VERSION "MG Windsor EV PRO - uCANdo profile (derived from the MG Commute pack, same platform)"

NS_ :

BS_:

BU_:

BO_ 288 HSC_Odometer: 5 Vector__XXX
 SG_ Odometer : 7|32@0+ (0.015625,0) [0|67108864] "km" Vector__XXX

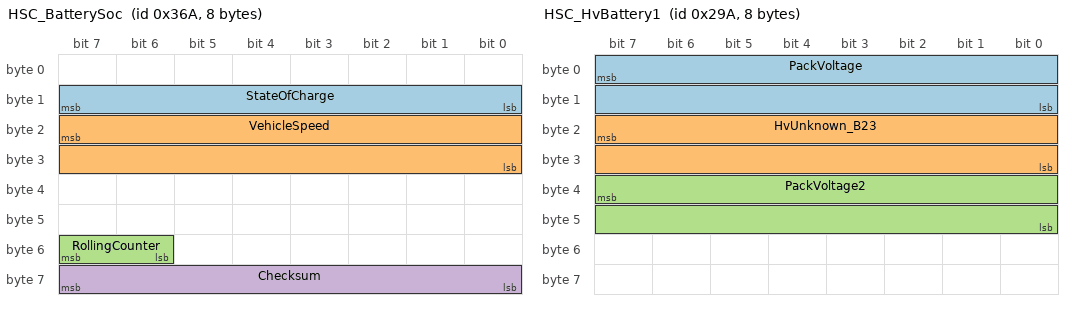
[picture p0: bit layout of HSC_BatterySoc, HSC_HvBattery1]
BO_ 874 HSC_BatterySoc: 8 Vector__XXX
 SG_ StateOfCharge : 15|8@0+ (0.5,0) [0|127.5] "%" Vector__XXX
 SG_ VehicleSpeed : 23|16@0+ (0.015625,0) [0|1023] "km/h" Vector__XXX
 SG_ RollingCounter : 55|2@0+ (1,0) [0|3] "" Vector__XXX
 SG_ Checksum : 63|8@0+ (1,0) [0|255] "" Vector__XXX

BO_ 364 HSC_VehicleSpeedHiRes: 8 Vector__XXX
 SG_ VehicleSpeedSigned : 23|16@0+ (0.01,-327.68) [-327.68|327.67] "km/h" Vector__XXX

BO_ 1221 HSC_RangeToEmpty: 8 Vector__XXX
 SG_ RangeToEmpty : 10|11@0+ (1,0) [0|2047] "km" Vector__XXX

BO_ 666 HSC_HvBattery1: 8 Vector__XXX
 SG_ PackVoltage : 7|16@0+ (0.1,0) [0|1000] "V" Vector__XXX
 SG_ HvUnknown_B23 : 23|16@0+ (0.1,0) [0|1000] "V" Vector__XXX
 SG_ PackVoltage2 : 39|16@0+ (0.1,0) [0|1000] "V" Vector__XXX

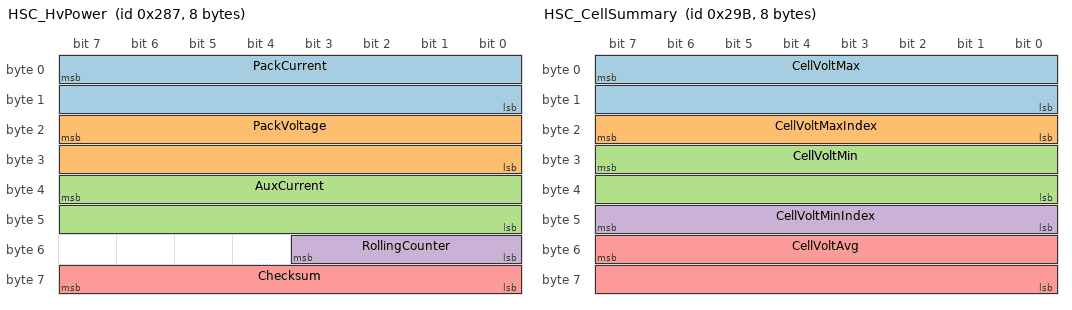
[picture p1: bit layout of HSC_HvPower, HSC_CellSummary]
BO_ 647 HSC_HvPower: 8 Vector__XXX
 SG_ PackCurrent : 7|16@0+ (0.1,-1000) [-1000|5535] "A" Vector__XXX
 SG_ PackVoltage : 23|16@0+ (0.1,0) [0|1000] "V" Vector__XXX
 SG_ AuxCurrent : 39|16@0+ (0.1,-1000) [-1000|5535] "A" Vector__XXX
 SG_ RollingCounter : 51|4@0+ (1,0) [0|15] "" Vector__XXX
 SG_ Checksum : 63|8@0+ (1,0) [0|255] "" Vector__XXX

BO_ 644 HSC_HvBattery2: 8 Vector__XXX
 SG_ PackVoltage : 23|16@0+ (0.1,0) [0|1000] "V" Vector__XXX

BO_ 667 HSC_CellSummary: 8 Vector__XXX
 SG_ CellVoltMax : 7|16@0+ (0.001,0) [0|65.535] "V" Vector__XXX
 SG_ CellVoltMaxIndex : 23|8@0+ (1,0) [0|255] "" Vector__XXX
 SG_ CellVoltMin : 31|16@0+ (0.001,0) [0|65.535] "V" Vector__XXX
 SG_ CellVoltMinIndex : 47|8@0+ (1,0) [0|255] "" Vector__XXX
 SG_ CellVoltAvg : 55|16@0+ (0.001,0) [0|65.535] "V" Vector__XXX

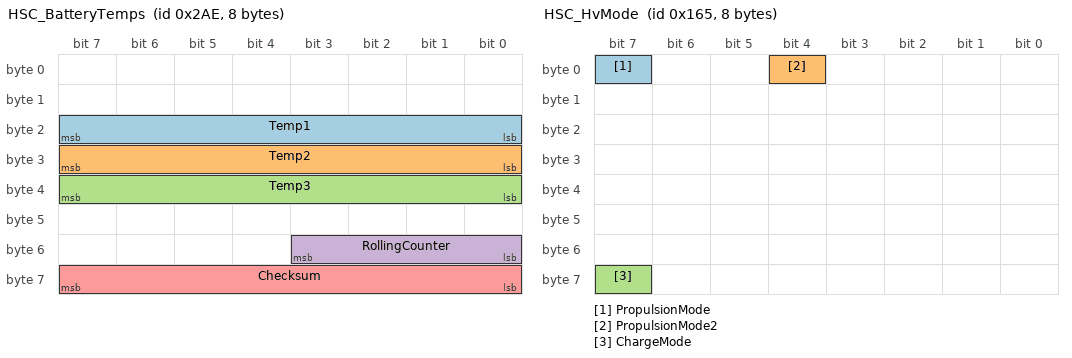
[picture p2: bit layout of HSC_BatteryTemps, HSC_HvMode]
BO_ 686 HSC_BatteryTemps: 8 Vector__XXX
 SG_ Temp1 : 23|8@0+ (1,-40) [-40|215] "degC" Vector__XXX
 SG_ Temp2 : 31|8@0+ (1,-40) [-40|215] "degC" Vector__XXX
 SG_ Temp3 : 39|8@0+ (1,-40) [-40|215] "degC" Vector__XXX
 SG_ RollingCounter : 51|4@0+ (1,0) [0|15] "" Vector__XXX
 SG_ Checksum : 63|8@0+ (1,0) [0|255] "" Vector__XXX

BO_ 1465 HSC_BatterySoh: 8 Vector__XXX
 SG_ SohPercent : 39|8@0+ (1,0) [0|255] "%" Vector__XXX
 SG_ SocPercent : 47|8@0+ (1,0) [0|255] "%" Vector__XXX

BO_ 878 HSC_ChargeTimer: 8 Vector__XXX
 SG_ TimeToFullCharge : 15|16@0+ (1,0) [0|65535] "min" Vector__XXX

BO_ 661 HSC_ChargeStatus: 8 Vector__XXX
 SG_ ChargingActive : 28|1@0+ (1,0) [0|1] "" Vector__XXX
 SG_ ChargerCableStatus : 10|2@0+ (1,0) [0|3] "" Vector__XXX

BO_ 1158 HSC_CellTemps: 8 Vector__XXX
 SG_ CellTemp_B6 : 55|8@0+ (1,-40) [-40|215] "degC" Vector__XXX
 SG_ CellTemp_B7 : 63|8@0+ (1,-40) [-40|215] "degC" Vector__XXX

BO_ 840 HSC_VehicleSpeed3: 6 Vector__XXX
 SG_ VehicleSpeed3 : 7|16@0+ (0.02,0) [0|1310] "km/h" Vector__XXX

BO_ 357 HSC_HvMode: 8 Vector__XXX
 SG_ PropulsionMode : 7|1@0+ (1,0) [0|1] "" Vector__XXX
 SG_ PropulsionMode2 : 4|1@0+ (1,0) [0|1] "" Vector__XXX
 SG_ ChargeMode : 63|1@0+ (1,0) [0|1] "" Vector__XXX

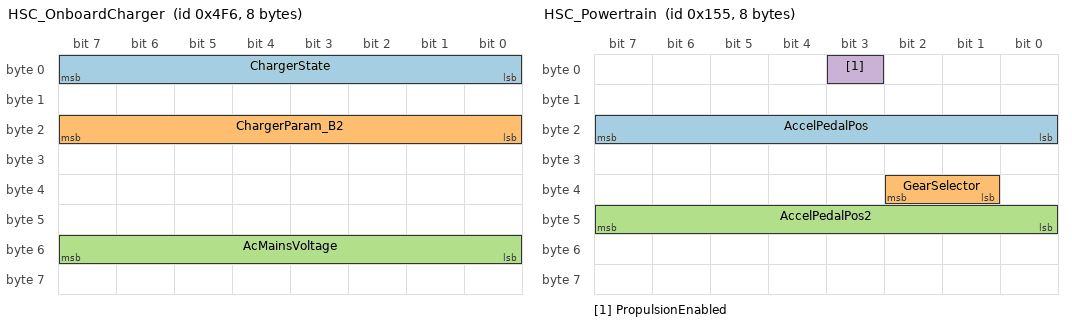
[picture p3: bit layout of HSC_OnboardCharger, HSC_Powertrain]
BO_ 1270 HSC_OnboardCharger: 8 Vector__XXX
 SG_ ChargerState : 7|8@0+ (1,0) [0|255] "" Vector__XXX
 SG_ ChargerParam_B2 : 23|8@0+ (1,0) [0|255] "" Vector__XXX
 SG_ AcMainsVoltage : 55|8@0+ (1,0) [0|255] "" Vector__XXX

BO_ 341 HSC_Powertrain: 8 Vector__XXX
 SG_ AccelPedalPos : 23|8@0+ (1,0) [0|100] "%" Vector__XXX
 SG_ GearSelector : 34|2@0+ (1,0) [0|3] "" Vector__XXX
 SG_ AccelPedalPos2 : 47|8@0+ (1,0) [0|100] "%" Vector__XXX
 SG_ PropulsionEnabled : 3|1@0+ (1,0) [0|1] "" Vector__XXX

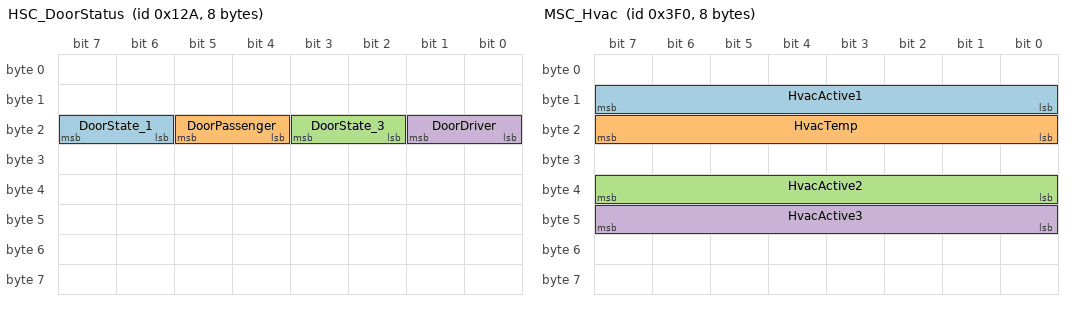
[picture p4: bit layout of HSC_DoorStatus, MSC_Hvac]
BO_ 298 HSC_DoorStatus: 8 Vector__XXX
 SG_ DoorState_1 : 23|2@0+ (1,0) [0|3] "" Vector__XXX
 SG_ DoorPassenger : 21|2@0+ (1,0) [0|3] "" Vector__XXX
 SG_ DoorState_3 : 19|2@0+ (1,0) [0|3] "" Vector__XXX
 SG_ DoorDriver : 17|2@0+ (1,0) [0|3] "" Vector__XXX

BO_ 225 HSC_SeatBelt: 8 Vector__XXX
 SG_ DriverSeatBelt : 11|1@0+ (1,0) [0|1] "" Vector__XXX
 SG_ Checksum : 63|8@0+ (1,0) [0|255] "" Vector__XXX

BO_ 663 HSC_TurnHazard: 8 Vector__XXX
 SG_ HazardSwitch : 38|1@0+ (1,0) [0|1] "" Vector__XXX
 SG_ TurnUnknown_bit32 : 39|1@0+ (1,0) [0|1] "" Vector__XXX

BO_ 633 HSC_LightSwitch: 8 Vector__XXX
 SG_ LightSwitchState : 27|3@0+ (1,0) [0|7] "" Vector__XXX

BO_ 1083 HSC_AcState: 8 Vector__XXX
 SG_ AcState : 13|2@0+ (1,0) [0|3] "" Vector__XXX

BO_ 1008 MSC_Hvac: 8 Vector__XXX
 SG_ HvacActive1 : 15|8@0+ (1,0) [0|255] "" Vector__XXX
 SG_ HvacTemp : 23|8@0+ (1,0) [0|255] "" Vector__XXX
 SG_ HvacActive2 : 39|8@0+ (1,0) [0|255] "" Vector__XXX
 SG_ HvacActive3 : 47|8@0+ (1,0) [0|255] "" Vector__XXX

BO_ 651 HSC_BrakePedal: 8 Vector__XXX
 SG_ BrakeSignal : 15|8@0+ (1,0) [0|255] "" Vector__XXX
 SG_ BrakeSignal2 : 47|8@0+ (1,0) [0|255] "" Vector__XXX

BO_ 1381 HSC_Unknown565: 8 Vector__XXX
 SG_ ParkBrakeCandidate : 6|1@0+ (1,0) [0|1] "" Vector__XXX

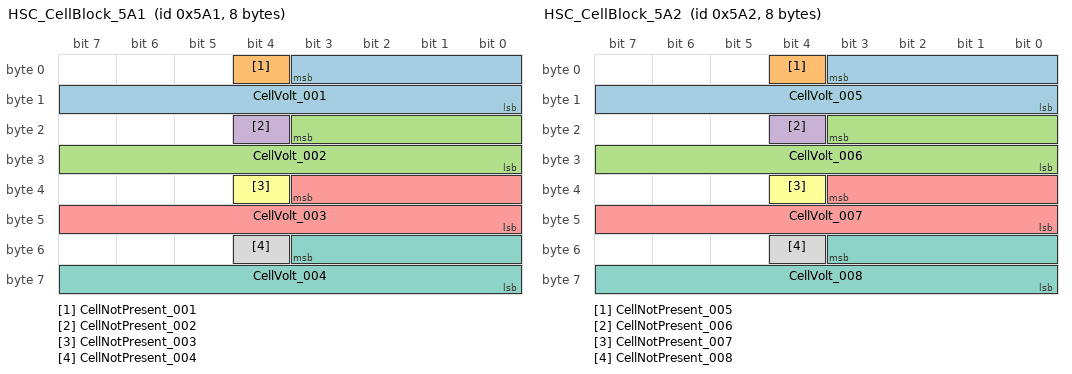
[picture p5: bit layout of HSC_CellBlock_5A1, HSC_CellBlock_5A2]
BO_ 1441 HSC_CellBlock_5A1: 8 Vector__XXX
 SG_ CellVolt_001 : 3|12@0+ (0.001,0) [0|4.095] "V" Vector__XXX
 SG_ CellNotPresent_001 : 4|1@0+ (1,0) [0|1] "" Vector__XXX
 SG_ CellVolt_002 : 19|12@0+ (0.001,0) [0|4.095] "V" Vector__XXX
 SG_ CellNotPresent_002 : 20|1@0+ (1,0) [0|1] "" Vector__XXX
 SG_ CellVolt_003 : 35|12@0+ (0.001,0) [0|4.095] "V" Vector__XXX
 SG_ CellNotPresent_003 : 36|1@0+ (1,0) [0|1] "" Vector__XXX
 SG_ CellVolt_004 : 51|12@0+ (0.001,0) [0|4.095] "V" Vector__XXX
 SG_ CellNotPresent_004 : 52|1@0+ (1,0) [0|1] "" Vector__XXX

BO_ 1442 HSC_CellBlock_5A2: 8 Vector__XXX
 SG_ CellVolt_005 : 3|12@0+ (0.001,0) [0|4.095] "V" Vector__XXX
 SG_ CellNotPresent_005 : 4|1@0+ (1,0) [0|1] "" Vector__XXX
 SG_ CellVolt_006 : 19|12@0+ (0.001,0) [0|4.095] "V" Vector__XXX
 SG_ CellNotPresent_006 : 20|1@0+ (1,0) [0|1] "" Vector__XXX
 SG_ CellVolt_007 : 35|12@0+ (0.001,0) [0|4.095] "V" Vector__XXX
 SG_ CellNotPresent_007 : 36|1@0+ (1,0) [0|1] "" Vector__XXX
 SG_ CellVolt_008 : 51|12@0+ (0.001,0) [0|4.095] "V" Vector__XXX
 SG_ CellNotPresent_008 : 52|1@0+ (1,0) [0|1] "" Vector__XXX

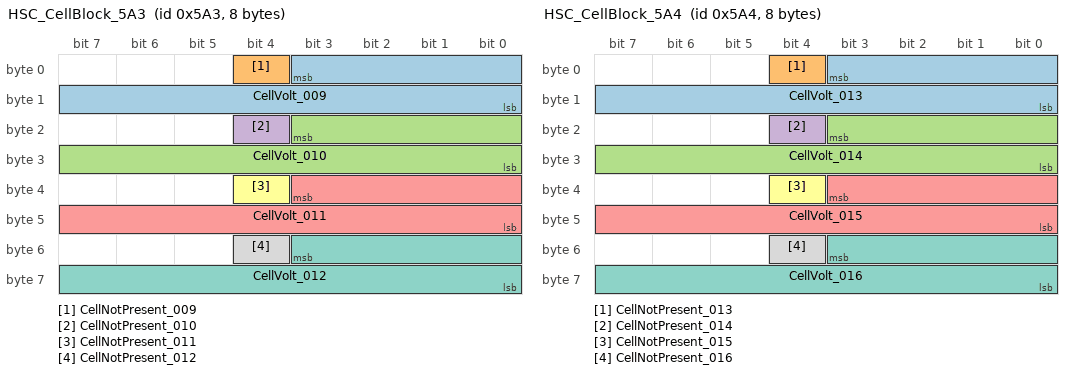
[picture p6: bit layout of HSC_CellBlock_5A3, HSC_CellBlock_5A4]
BO_ 1443 HSC_CellBlock_5A3: 8 Vector__XXX
 SG_ CellVolt_009 : 3|12@0+ (0.001,0) [0|4.095] "V" Vector__XXX
 SG_ CellNotPresent_009 : 4|1@0+ (1,0) [0|1] "" Vector__XXX
 SG_ CellVolt_010 : 19|12@0+ (0.001,0) [0|4.095] "V" Vector__XXX
 SG_ CellNotPresent_010 : 20|1@0+ (1,0) [0|1] "" Vector__XXX
 SG_ CellVolt_011 : 35|12@0+ (0.001,0) [0|4.095] "V" Vector__XXX
 SG_ CellNotPresent_011 : 36|1@0+ (1,0) [0|1] "" Vector__XXX
 SG_ CellVolt_012 : 51|12@0+ (0.001,0) [0|4.095] "V" Vector__XXX
 SG_ CellNotPresent_012 : 52|1@0+ (1,0) [0|1] "" Vector__XXX

BO_ 1444 HSC_CellBlock_5A4: 8 Vector__XXX
 SG_ CellVolt_013 : 3|12@0+ (0.001,0) [0|4.095] "V" Vector__XXX
 SG_ CellNotPresent_013 : 4|1@0+ (1,0) [0|1] "" Vector__XXX
 SG_ CellVolt_014 : 19|12@0+ (0.001,0) [0|4.095] "V" Vector__XXX
 SG_ CellNotPresent_014 : 20|1@0+ (1,0) [0|1] "" Vector__XXX
 SG_ CellVolt_015 : 35|12@0+ (0.001,0) [0|4.095] "V" Vector__XXX
 SG_ CellNotPresent_015 : 36|1@0+ (1,0) [0|1] "" Vector__XXX
 SG_ CellVolt_016 : 51|12@0+ (0.001,0) [0|4.095] "V" Vector__XXX
 SG_ CellNotPresent_016 : 52|1@0+ (1,0) [0|1] "" Vector__XXX

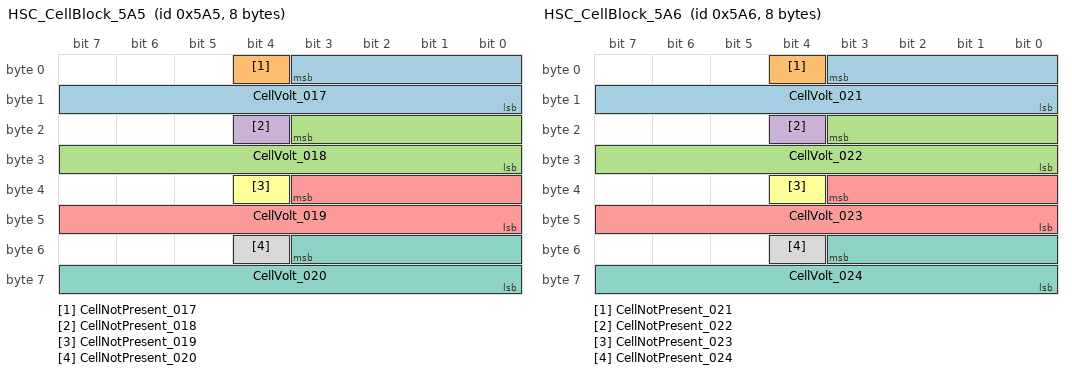
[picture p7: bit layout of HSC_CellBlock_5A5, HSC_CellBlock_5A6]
BO_ 1445 HSC_CellBlock_5A5: 8 Vector__XXX
 SG_ CellVolt_017 : 3|12@0+ (0.001,0) [0|4.095] "V" Vector__XXX
 SG_ CellNotPresent_017 : 4|1@0+ (1,0) [0|1] "" Vector__XXX
 SG_ CellVolt_018 : 19|12@0+ (0.001,0) [0|4.095] "V" Vector__XXX
 SG_ CellNotPresent_018 : 20|1@0+ (1,0) [0|1] "" Vector__XXX
 SG_ CellVolt_019 : 35|12@0+ (0.001,0) [0|4.095] "V" Vector__XXX
 SG_ CellNotPresent_019 : 36|1@0+ (1,0) [0|1] "" Vector__XXX
 SG_ CellVolt_020 : 51|12@0+ (0.001,0) [0|4.095] "V" Vector__XXX
 SG_ CellNotPresent_020 : 52|1@0+ (1,0) [0|1] "" Vector__XXX

BO_ 1446 HSC_CellBlock_5A6: 8 Vector__XXX
 SG_ CellVolt_021 : 3|12@0+ (0.001,0) [0|4.095] "V" Vector__XXX
 SG_ CellNotPresent_021 : 4|1@0+ (1,0) [0|1] "" Vector__XXX
 SG_ CellVolt_022 : 19|12@0+ (0.001,0) [0|4.095] "V" Vector__XXX
 SG_ CellNotPresent_022 : 20|1@0+ (1,0) [0|1] "" Vector__XXX
 SG_ CellVolt_023 : 35|12@0+ (0.001,0) [0|4.095] "V" Vector__XXX
 SG_ CellNotPresent_023 : 36|1@0+ (1,0) [0|1] "" Vector__XXX
 SG_ CellVolt_024 : 51|12@0+ (0.001,0) [0|4.095] "V" Vector__XXX
 SG_ CellNotPresent_024 : 52|1@0+ (1,0) [0|1] "" Vector__XXX

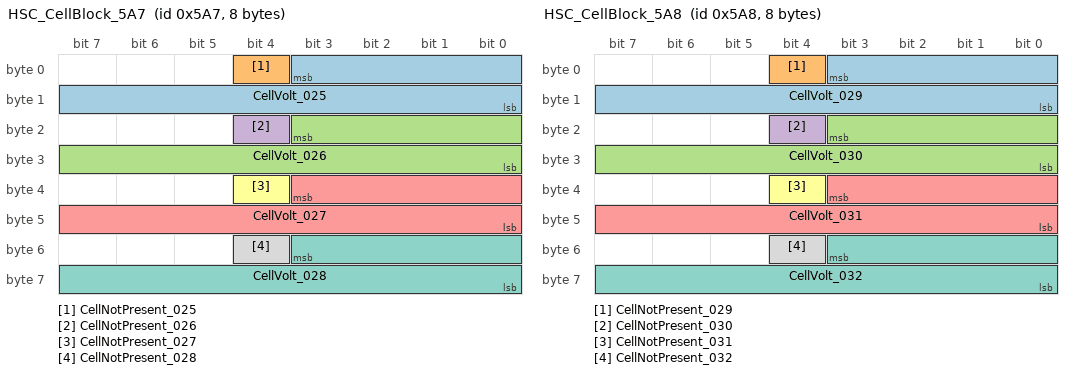
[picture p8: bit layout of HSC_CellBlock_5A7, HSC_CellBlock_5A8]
BO_ 1447 HSC_CellBlock_5A7: 8 Vector__XXX
 SG_ CellVolt_025 : 3|12@0+ (0.001,0) [0|4.095] "V" Vector__XXX
 SG_ CellNotPresent_025 : 4|1@0+ (1,0) [0|1] "" Vector__XXX
 SG_ CellVolt_026 : 19|12@0+ (0.001,0) [0|4.095] "V" Vector__XXX
 SG_ CellNotPresent_026 : 20|1@0+ (1,0) [0|1] "" Vector__XXX
 SG_ CellVolt_027 : 35|12@0+ (0.001,0) [0|4.095] "V" Vector__XXX
 SG_ CellNotPresent_027 : 36|1@0+ (1,0) [0|1] "" Vector__XXX
 SG_ CellVolt_028 : 51|12@0+ (0.001,0) [0|4.095] "V" Vector__XXX
 SG_ CellNotPresent_028 : 52|1@0+ (1,0) [0|1] "" Vector__XXX

BO_ 1448 HSC_CellBlock_5A8: 8 Vector__XXX
 SG_ CellVolt_029 : 3|12@0+ (0.001,0) [0|4.095] "V" Vector__XXX
 SG_ CellNotPresent_029 : 4|1@0+ (1,0) [0|1] "" Vector__XXX
 SG_ CellVolt_030 : 19|12@0+ (0.001,0) [0|4.095] "V" Vector__XXX
 SG_ CellNotPresent_030 : 20|1@0+ (1,0) [0|1] "" Vector__XXX
 SG_ CellVolt_031 : 35|12@0+ (0.001,0) [0|4.095] "V" Vector__XXX
 SG_ CellNotPresent_031 : 36|1@0+ (1,0) [0|1] "" Vector__XXX
 SG_ CellVolt_032 : 51|12@0+ (0.001,0) [0|4.095] "V" Vector__XXX
 SG_ CellNotPresent_032 : 52|1@0+ (1,0) [0|1] "" Vector__XXX

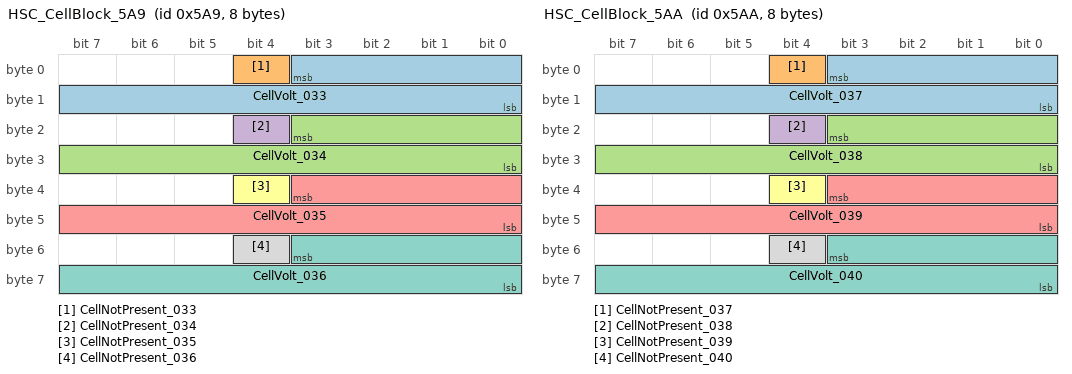
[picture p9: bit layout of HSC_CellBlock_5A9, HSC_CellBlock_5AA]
BO_ 1449 HSC_CellBlock_5A9: 8 Vector__XXX
 SG_ CellVolt_033 : 3|12@0+ (0.001,0) [0|4.095] "V" Vector__XXX
 SG_ CellNotPresent_033 : 4|1@0+ (1,0) [0|1] "" Vector__XXX
 SG_ CellVolt_034 : 19|12@0+ (0.001,0) [0|4.095] "V" Vector__XXX
 SG_ CellNotPresent_034 : 20|1@0+ (1,0) [0|1] "" Vector__XXX
 SG_ CellVolt_035 : 35|12@0+ (0.001,0) [0|4.095] "V" Vector__XXX
 SG_ CellNotPresent_035 : 36|1@0+ (1,0) [0|1] "" Vector__XXX
 SG_ CellVolt_036 : 51|12@0+ (0.001,0) [0|4.095] "V" Vector__XXX
 SG_ CellNotPresent_036 : 52|1@0+ (1,0) [0|1] "" Vector__XXX

BO_ 1450 HSC_CellBlock_5AA: 8 Vector__XXX
 SG_ CellVolt_037 : 3|12@0+ (0.001,0) [0|4.095] "V" Vector__XXX
 SG_ CellNotPresent_037 : 4|1@0+ (1,0) [0|1] "" Vector__XXX
 SG_ CellVolt_038 : 19|12@0+ (0.001,0) [0|4.095] "V" Vector__XXX
 SG_ CellNotPresent_038 : 20|1@0+ (1,0) [0|1] "" Vector__XXX
 SG_ CellVolt_039 : 35|12@0+ (0.001,0) [0|4.095] "V" Vector__XXX
 SG_ CellNotPresent_039 : 36|1@0+ (1,0) [0|1] "" Vector__XXX
 SG_ CellVolt_040 : 51|12@0+ (0.001,0) [0|4.095] "V" Vector__XXX
 SG_ CellNotPresent_040 : 52|1@0+ (1,0) [0|1] "" Vector__XXX

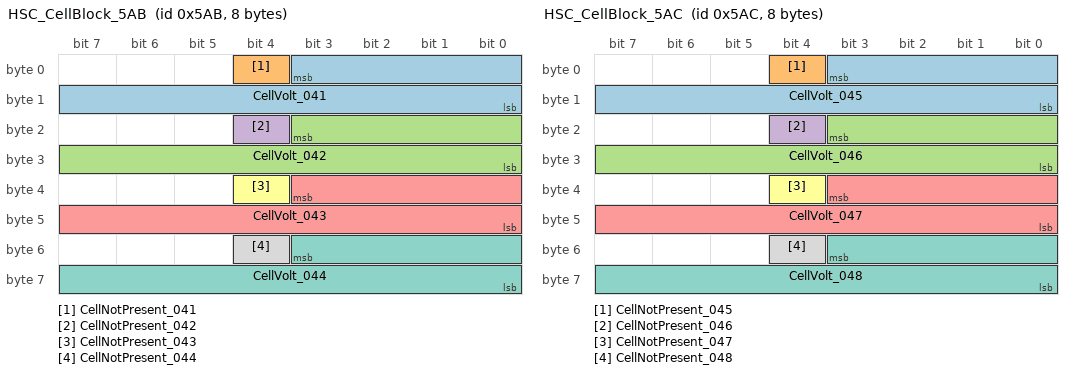
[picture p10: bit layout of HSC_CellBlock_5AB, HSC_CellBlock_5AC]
BO_ 1451 HSC_CellBlock_5AB: 8 Vector__XXX
 SG_ CellVolt_041 : 3|12@0+ (0.001,0) [0|4.095] "V" Vector__XXX
 SG_ CellNotPresent_041 : 4|1@0+ (1,0) [0|1] "" Vector__XXX
 SG_ CellVolt_042 : 19|12@0+ (0.001,0) [0|4.095] "V" Vector__XXX
 SG_ CellNotPresent_042 : 20|1@0+ (1,0) [0|1] "" Vector__XXX
 SG_ CellVolt_043 : 35|12@0+ (0.001,0) [0|4.095] "V" Vector__XXX
 SG_ CellNotPresent_043 : 36|1@0+ (1,0) [0|1] "" Vector__XXX
 SG_ CellVolt_044 : 51|12@0+ (0.001,0) [0|4.095] "V" Vector__XXX
 SG_ CellNotPresent_044 : 52|1@0+ (1,0) [0|1] "" Vector__XXX

BO_ 1452 HSC_CellBlock_5AC: 8 Vector__XXX
 SG_ CellVolt_045 : 3|12@0+ (0.001,0) [0|4.095] "V" Vector__XXX
 SG_ CellNotPresent_045 : 4|1@0+ (1,0) [0|1] "" Vector__XXX
 SG_ CellVolt_046 : 19|12@0+ (0.001,0) [0|4.095] "V" Vector__XXX
 SG_ CellNotPresent_046 : 20|1@0+ (1,0) [0|1] "" Vector__XXX
 SG_ CellVolt_047 : 35|12@0+ (0.001,0) [0|4.095] "V" Vector__XXX
 SG_ CellNotPresent_047 : 36|1@0+ (1,0) [0|1] "" Vector__XXX
 SG_ CellVolt_048 : 51|12@0+ (0.001,0) [0|4.095] "V" Vector__XXX
 SG_ CellNotPresent_048 : 52|1@0+ (1,0) [0|1] "" Vector__XXX

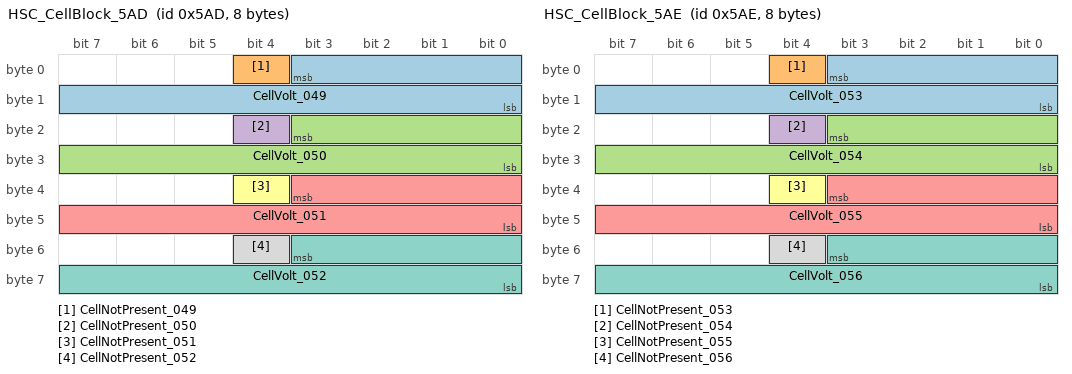
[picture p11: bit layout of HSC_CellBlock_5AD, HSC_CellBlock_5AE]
BO_ 1453 HSC_CellBlock_5AD: 8 Vector__XXX
 SG_ CellVolt_049 : 3|12@0+ (0.001,0) [0|4.095] "V" Vector__XXX
 SG_ CellNotPresent_049 : 4|1@0+ (1,0) [0|1] "" Vector__XXX
 SG_ CellVolt_050 : 19|12@0+ (0.001,0) [0|4.095] "V" Vector__XXX
 SG_ CellNotPresent_050 : 20|1@0+ (1,0) [0|1] "" Vector__XXX
 SG_ CellVolt_051 : 35|12@0+ (0.001,0) [0|4.095] "V" Vector__XXX
 SG_ CellNotPresent_051 : 36|1@0+ (1,0) [0|1] "" Vector__XXX
 SG_ CellVolt_052 : 51|12@0+ (0.001,0) [0|4.095] "V" Vector__XXX
 SG_ CellNotPresent_052 : 52|1@0+ (1,0) [0|1] "" Vector__XXX

BO_ 1454 HSC_CellBlock_5AE: 8 Vector__XXX
 SG_ CellVolt_053 : 3|12@0+ (0.001,0) [0|4.095] "V" Vector__XXX
 SG_ CellNotPresent_053 : 4|1@0+ (1,0) [0|1] "" Vector__XXX
 SG_ CellVolt_054 : 19|12@0+ (0.001,0) [0|4.095] "V" Vector__XXX
 SG_ CellNotPresent_054 : 20|1@0+ (1,0) [0|1] "" Vector__XXX
 SG_ CellVolt_055 : 35|12@0+ (0.001,0) [0|4.095] "V" Vector__XXX
 SG_ CellNotPresent_055 : 36|1@0+ (1,0) [0|1] "" Vector__XXX
 SG_ CellVolt_056 : 51|12@0+ (0.001,0) [0|4.095] "V" Vector__XXX
 SG_ CellNotPresent_056 : 52|1@0+ (1,0) [0|1] "" Vector__XXX

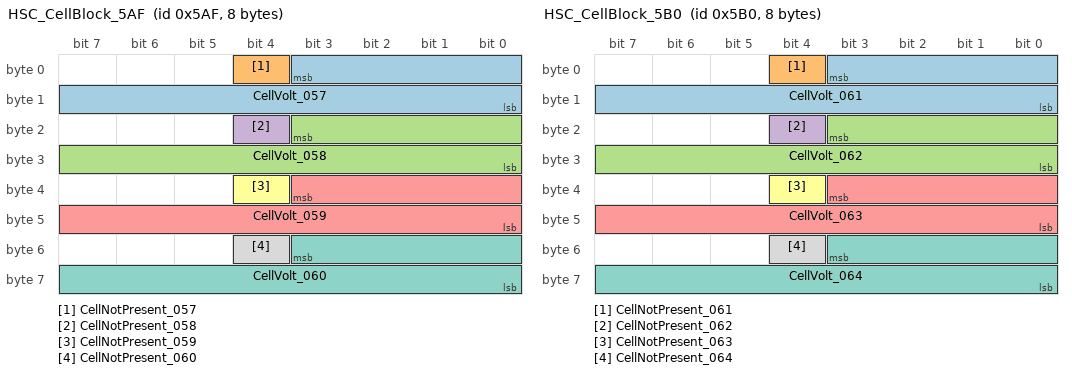
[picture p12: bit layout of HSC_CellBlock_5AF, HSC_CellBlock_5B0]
BO_ 1455 HSC_CellBlock_5AF: 8 Vector__XXX
 SG_ CellVolt_057 : 3|12@0+ (0.001,0) [0|4.095] "V" Vector__XXX
 SG_ CellNotPresent_057 : 4|1@0+ (1,0) [0|1] "" Vector__XXX
 SG_ CellVolt_058 : 19|12@0+ (0.001,0) [0|4.095] "V" Vector__XXX
 SG_ CellNotPresent_058 : 20|1@0+ (1,0) [0|1] "" Vector__XXX
 SG_ CellVolt_059 : 35|12@0+ (0.001,0) [0|4.095] "V" Vector__XXX
 SG_ CellNotPresent_059 : 36|1@0+ (1,0) [0|1] "" Vector__XXX
 SG_ CellVolt_060 : 51|12@0+ (0.001,0) [0|4.095] "V" Vector__XXX
 SG_ CellNotPresent_060 : 52|1@0+ (1,0) [0|1] "" Vector__XXX

BO_ 1456 HSC_CellBlock_5B0: 8 Vector__XXX
 SG_ CellVolt_061 : 3|12@0+ (0.001,0) [0|4.095] "V" Vector__XXX
 SG_ CellNotPresent_061 : 4|1@0+ (1,0) [0|1] "" Vector__XXX
 SG_ CellVolt_062 : 19|12@0+ (0.001,0) [0|4.095] "V" Vector__XXX
 SG_ CellNotPresent_062 : 20|1@0+ (1,0) [0|1] "" Vector__XXX
 SG_ CellVolt_063 : 35|12@0+ (0.001,0) [0|4.095] "V" Vector__XXX
 SG_ CellNotPresent_063 : 36|1@0+ (1,0) [0|1] "" Vector__XXX
 SG_ CellVolt_064 : 51|12@0+ (0.001,0) [0|4.095] "V" Vector__XXX
 SG_ CellNotPresent_064 : 52|1@0+ (1,0) [0|1] "" Vector__XXX

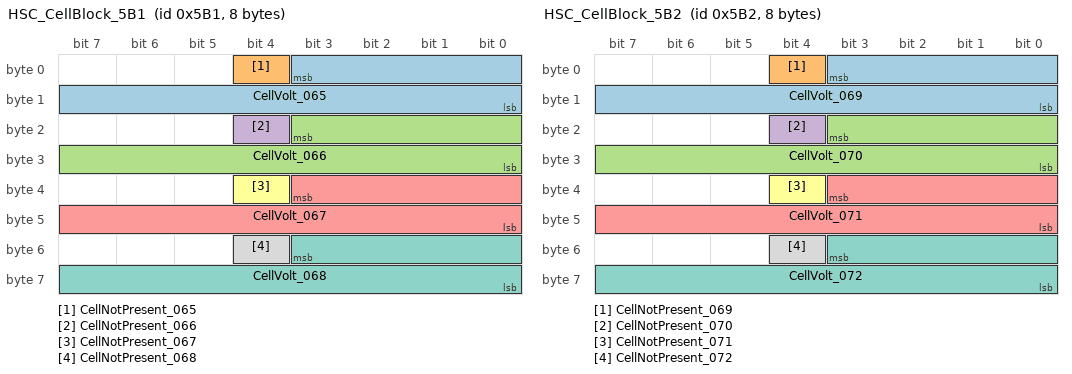
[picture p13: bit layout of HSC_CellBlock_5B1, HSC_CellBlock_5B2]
BO_ 1457 HSC_CellBlock_5B1: 8 Vector__XXX
 SG_ CellVolt_065 : 3|12@0+ (0.001,0) [0|4.095] "V" Vector__XXX
 SG_ CellNotPresent_065 : 4|1@0+ (1,0) [0|1] "" Vector__XXX
 SG_ CellVolt_066 : 19|12@0+ (0.001,0) [0|4.095] "V" Vector__XXX
 SG_ CellNotPresent_066 : 20|1@0+ (1,0) [0|1] "" Vector__XXX
 SG_ CellVolt_067 : 35|12@0+ (0.001,0) [0|4.095] "V" Vector__XXX
 SG_ CellNotPresent_067 : 36|1@0+ (1,0) [0|1] "" Vector__XXX
 SG_ CellVolt_068 : 51|12@0+ (0.001,0) [0|4.095] "V" Vector__XXX
 SG_ CellNotPresent_068 : 52|1@0+ (1,0) [0|1] "" Vector__XXX

BO_ 1458 HSC_CellBlock_5B2: 8 Vector__XXX
 SG_ CellVolt_069 : 3|12@0+ (0.001,0) [0|4.095] "V" Vector__XXX
 SG_ CellNotPresent_069 : 4|1@0+ (1,0) [0|1] "" Vector__XXX
 SG_ CellVolt_070 : 19|12@0+ (0.001,0) [0|4.095] "V" Vector__XXX
 SG_ CellNotPresent_070 : 20|1@0+ (1,0) [0|1] "" Vector__XXX
 SG_ CellVolt_071 : 35|12@0+ (0.001,0) [0|4.095] "V" Vector__XXX
 SG_ CellNotPresent_071 : 36|1@0+ (1,0) [0|1] "" Vector__XXX
 SG_ CellVolt_072 : 51|12@0+ (0.001,0) [0|4.095] "V" Vector__XXX
 SG_ CellNotPresent_072 : 52|1@0+ (1,0) [0|1] "" Vector__XXX

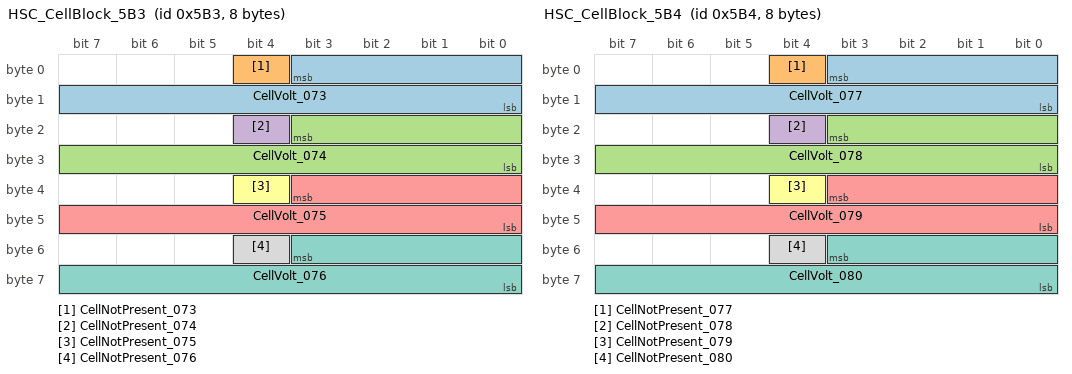
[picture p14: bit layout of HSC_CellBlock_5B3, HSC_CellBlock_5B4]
BO_ 1459 HSC_CellBlock_5B3: 8 Vector__XXX
 SG_ CellVolt_073 : 3|12@0+ (0.001,0) [0|4.095] "V" Vector__XXX
 SG_ CellNotPresent_073 : 4|1@0+ (1,0) [0|1] "" Vector__XXX
 SG_ CellVolt_074 : 19|12@0+ (0.001,0) [0|4.095] "V" Vector__XXX
 SG_ CellNotPresent_074 : 20|1@0+ (1,0) [0|1] "" Vector__XXX
 SG_ CellVolt_075 : 35|12@0+ (0.001,0) [0|4.095] "V" Vector__XXX
 SG_ CellNotPresent_075 : 36|1@0+ (1,0) [0|1] "" Vector__XXX
 SG_ CellVolt_076 : 51|12@0+ (0.001,0) [0|4.095] "V" Vector__XXX
 SG_ CellNotPresent_076 : 52|1@0+ (1,0) [0|1] "" Vector__XXX

BO_ 1460 HSC_CellBlock_5B4: 8 Vector__XXX
 SG_ CellVolt_077 : 3|12@0+ (0.001,0) [0|4.095] "V" Vector__XXX
 SG_ CellNotPresent_077 : 4|1@0+ (1,0) [0|1] "" Vector__XXX
 SG_ CellVolt_078 : 19|12@0+ (0.001,0) [0|4.095] "V" Vector__XXX
 SG_ CellNotPresent_078 : 20|1@0+ (1,0) [0|1] "" Vector__XXX
 SG_ CellVolt_079 : 35|12@0+ (0.001,0) [0|4.095] "V" Vector__XXX
 SG_ CellNotPresent_079 : 36|1@0+ (1,0) [0|1] "" Vector__XXX
 SG_ CellVolt_080 : 51|12@0+ (0.001,0) [0|4.095] "V" Vector__XXX
 SG_ CellNotPresent_080 : 52|1@0+ (1,0) [0|1] "" Vector__XXX

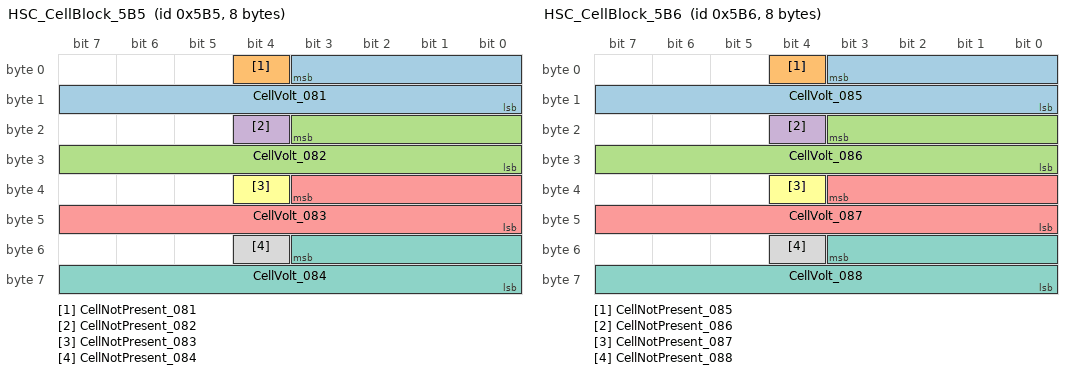
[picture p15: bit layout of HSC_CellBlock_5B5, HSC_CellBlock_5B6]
BO_ 1461 HSC_CellBlock_5B5: 8 Vector__XXX
 SG_ CellVolt_081 : 3|12@0+ (0.001,0) [0|4.095] "V" Vector__XXX
 SG_ CellNotPresent_081 : 4|1@0+ (1,0) [0|1] "" Vector__XXX
 SG_ CellVolt_082 : 19|12@0+ (0.001,0) [0|4.095] "V" Vector__XXX
 SG_ CellNotPresent_082 : 20|1@0+ (1,0) [0|1] "" Vector__XXX
 SG_ CellVolt_083 : 35|12@0+ (0.001,0) [0|4.095] "V" Vector__XXX
 SG_ CellNotPresent_083 : 36|1@0+ (1,0) [0|1] "" Vector__XXX
 SG_ CellVolt_084 : 51|12@0+ (0.001,0) [0|4.095] "V" Vector__XXX
 SG_ CellNotPresent_084 : 52|1@0+ (1,0) [0|1] "" Vector__XXX

BO_ 1462 HSC_CellBlock_5B6: 8 Vector__XXX
 SG_ CellVolt_085 : 3|12@0+ (0.001,0) [0|4.095] "V" Vector__XXX
 SG_ CellNotPresent_085 : 4|1@0+ (1,0) [0|1] "" Vector__XXX
 SG_ CellVolt_086 : 19|12@0+ (0.001,0) [0|4.095] "V" Vector__XXX
 SG_ CellNotPresent_086 : 20|1@0+ (1,0) [0|1] "" Vector__XXX
 SG_ CellVolt_087 : 35|12@0+ (0.001,0) [0|4.095] "V" Vector__XXX
 SG_ CellNotPresent_087 : 36|1@0+ (1,0) [0|1] "" Vector__XXX
 SG_ CellVolt_088 : 51|12@0+ (0.001,0) [0|4.095] "V" Vector__XXX
 SG_ CellNotPresent_088 : 52|1@0+ (1,0) [0|1] "" Vector__XXX

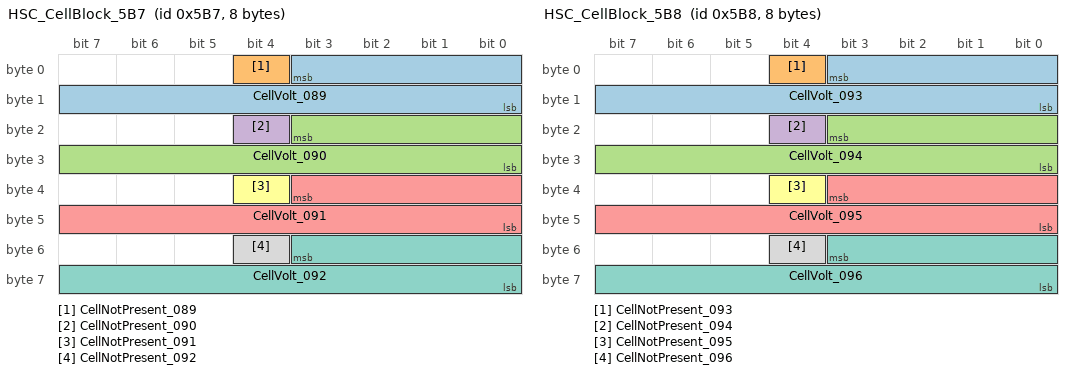
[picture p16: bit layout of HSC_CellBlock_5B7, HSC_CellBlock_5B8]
BO_ 1463 HSC_CellBlock_5B7: 8 Vector__XXX
 SG_ CellVolt_089 : 3|12@0+ (0.001,0) [0|4.095] "V" Vector__XXX
 SG_ CellNotPresent_089 : 4|1@0+ (1,0) [0|1] "" Vector__XXX
 SG_ CellVolt_090 : 19|12@0+ (0.001,0) [0|4.095] "V" Vector__XXX
 SG_ CellNotPresent_090 : 20|1@0+ (1,0) [0|1] "" Vector__XXX
 SG_ CellVolt_091 : 35|12@0+ (0.001,0) [0|4.095] "V" Vector__XXX
 SG_ CellNotPresent_091 : 36|1@0+ (1,0) [0|1] "" Vector__XXX
 SG_ CellVolt_092 : 51|12@0+ (0.001,0) [0|4.095] "V" Vector__XXX
 SG_ CellNotPresent_092 : 52|1@0+ (1,0) [0|1] "" Vector__XXX

BO_ 1464 HSC_CellBlock_5B8: 8 Vector__XXX
 SG_ CellVolt_093 : 3|12@0+ (0.001,0) [0|4.095] "V" Vector__XXX
 SG_ CellNotPresent_093 : 4|1@0+ (1,0) [0|1] "" Vector__XXX
 SG_ CellVolt_094 : 19|12@0+ (0.001,0) [0|4.095] "V" Vector__XXX
 SG_ CellNotPresent_094 : 20|1@0+ (1,0) [0|1] "" Vector__XXX
 SG_ CellVolt_095 : 35|12@0+ (0.001,0) [0|4.095] "V" Vector__XXX
 SG_ CellNotPresent_095 : 36|1@0+ (1,0) [0|1] "" Vector__XXX
 SG_ CellVolt_096 : 51|12@0+ (0.001,0) [0|4.095] "V" Vector__XXX
 SG_ CellNotPresent_096 : 52|1@0+ (1,0) [0|1] "" Vector__XXX

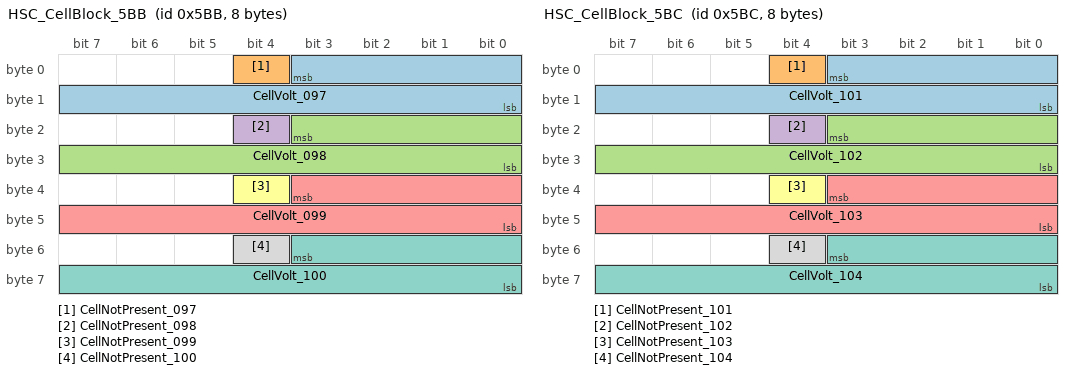
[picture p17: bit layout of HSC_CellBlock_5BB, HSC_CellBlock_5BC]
BO_ 1467 HSC_CellBlock_5BB: 8 Vector__XXX
 SG_ CellVolt_097 : 3|12@0+ (0.001,0) [0|4.095] "V" Vector__XXX
 SG_ CellNotPresent_097 : 4|1@0+ (1,0) [0|1] "" Vector__XXX
 SG_ CellVolt_098 : 19|12@0+ (0.001,0) [0|4.095] "V" Vector__XXX
 SG_ CellNotPresent_098 : 20|1@0+ (1,0) [0|1] "" Vector__XXX
 SG_ CellVolt_099 : 35|12@0+ (0.001,0) [0|4.095] "V" Vector__XXX
 SG_ CellNotPresent_099 : 36|1@0+ (1,0) [0|1] "" Vector__XXX
 SG_ CellVolt_100 : 51|12@0+ (0.001,0) [0|4.095] "V" Vector__XXX
 SG_ CellNotPresent_100 : 52|1@0+ (1,0) [0|1] "" Vector__XXX

BO_ 1468 HSC_CellBlock_5BC: 8 Vector__XXX
 SG_ CellVolt_101 : 3|12@0+ (0.001,0) [0|4.095] "V" Vector__XXX
 SG_ CellNotPresent_101 : 4|1@0+ (1,0) [0|1] "" Vector__XXX
 SG_ CellVolt_102 : 19|12@0+ (0.001,0) [0|4.095] "V" Vector__XXX
 SG_ CellNotPresent_102 : 20|1@0+ (1,0) [0|1] "" Vector__XXX
 SG_ CellVolt_103 : 35|12@0+ (0.001,0) [0|4.095] "V" Vector__XXX
 SG_ CellNotPresent_103 : 36|1@0+ (1,0) [0|1] "" Vector__XXX
 SG_ CellVolt_104 : 51|12@0+ (0.001,0) [0|4.095] "V" Vector__XXX
 SG_ CellNotPresent_104 : 52|1@0+ (1,0) [0|1] "" Vector__XXX

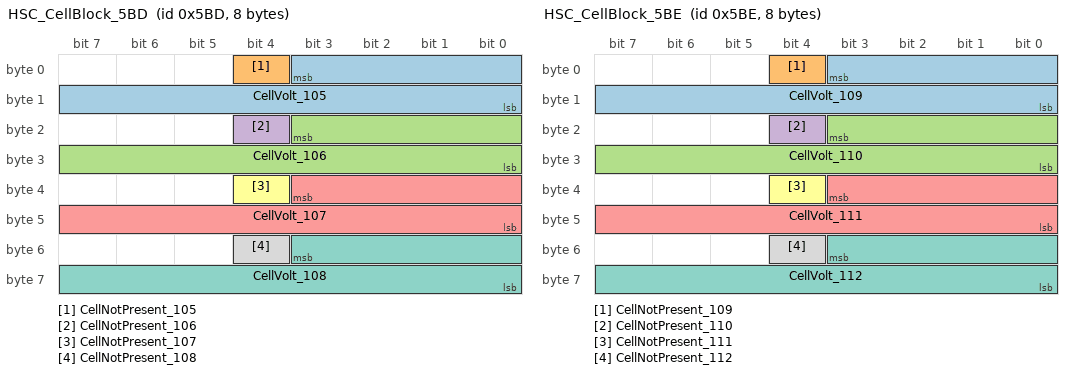
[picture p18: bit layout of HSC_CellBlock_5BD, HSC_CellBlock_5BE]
BO_ 1469 HSC_CellBlock_5BD: 8 Vector__XXX
 SG_ CellVolt_105 : 3|12@0+ (0.001,0) [0|4.095] "V" Vector__XXX
 SG_ CellNotPresent_105 : 4|1@0+ (1,0) [0|1] "" Vector__XXX
 SG_ CellVolt_106 : 19|12@0+ (0.001,0) [0|4.095] "V" Vector__XXX
 SG_ CellNotPresent_106 : 20|1@0+ (1,0) [0|1] "" Vector__XXX
 SG_ CellVolt_107 : 35|12@0+ (0.001,0) [0|4.095] "V" Vector__XXX
 SG_ CellNotPresent_107 : 36|1@0+ (1,0) [0|1] "" Vector__XXX
 SG_ CellVolt_108 : 51|12@0+ (0.001,0) [0|4.095] "V" Vector__XXX
 SG_ CellNotPresent_108 : 52|1@0+ (1,0) [0|1] "" Vector__XXX

BO_ 1470 HSC_CellBlock_5BE: 8 Vector__XXX
 SG_ CellVolt_109 : 3|12@0+ (0.001,0) [0|4.095] "V" Vector__XXX
 SG_ CellNotPresent_109 : 4|1@0+ (1,0) [0|1] "" Vector__XXX
 SG_ CellVolt_110 : 19|12@0+ (0.001,0) [0|4.095] "V" Vector__XXX
 SG_ CellNotPresent_110 : 20|1@0+ (1,0) [0|1] "" Vector__XXX
 SG_ CellVolt_111 : 35|12@0+ (0.001,0) [0|4.095] "V" Vector__XXX
 SG_ CellNotPresent_111 : 36|1@0+ (1,0) [0|1] "" Vector__XXX
 SG_ CellVolt_112 : 51|12@0+ (0.001,0) [0|4.095] "V" Vector__XXX
 SG_ CellNotPresent_112 : 52|1@0+ (1,0) [0|1] "" Vector__XXX

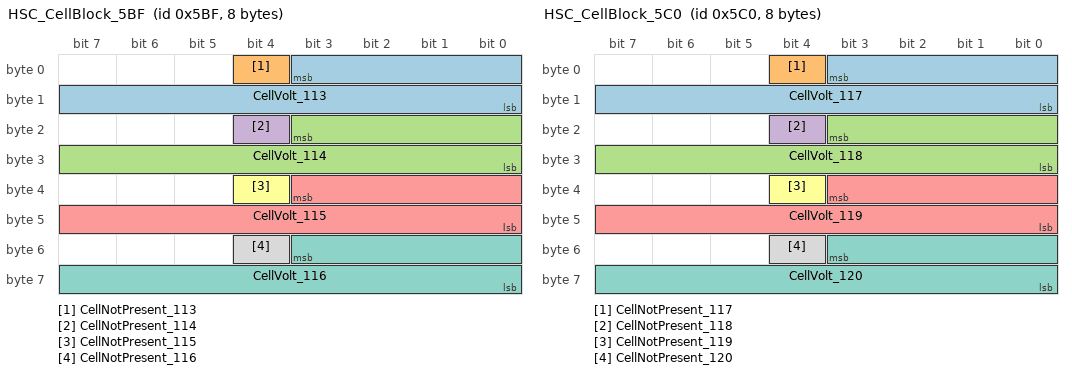
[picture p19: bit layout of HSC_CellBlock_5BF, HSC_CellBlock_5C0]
BO_ 1471 HSC_CellBlock_5BF: 8 Vector__XXX
 SG_ CellVolt_113 : 3|12@0+ (0.001,0) [0|4.095] "V" Vector__XXX
 SG_ CellNotPresent_113 : 4|1@0+ (1,0) [0|1] "" Vector__XXX
 SG_ CellVolt_114 : 19|12@0+ (0.001,0) [0|4.095] "V" Vector__XXX
 SG_ CellNotPresent_114 : 20|1@0+ (1,0) [0|1] "" Vector__XXX
 SG_ CellVolt_115 : 35|12@0+ (0.001,0) [0|4.095] "V" Vector__XXX
 SG_ CellNotPresent_115 : 36|1@0+ (1,0) [0|1] "" Vector__XXX
 SG_ CellVolt_116 : 51|12@0+ (0.001,0) [0|4.095] "V" Vector__XXX
 SG_ CellNotPresent_116 : 52|1@0+ (1,0) [0|1] "" Vector__XXX

BO_ 1472 HSC_CellBlock_5C0: 8 Vector__XXX
 SG_ CellVolt_117 : 3|12@0+ (0.001,0) [0|4.095] "V" Vector__XXX
 SG_ CellNotPresent_117 : 4|1@0+ (1,0) [0|1] "" Vector__XXX
 SG_ CellVolt_118 : 19|12@0+ (0.001,0) [0|4.095] "V" Vector__XXX
 SG_ CellNotPresent_118 : 20|1@0+ (1,0) [0|1] "" Vector__XXX
 SG_ CellVolt_119 : 35|12@0+ (0.001,0) [0|4.095] "V" Vector__XXX
 SG_ CellNotPresent_119 : 36|1@0+ (1,0) [0|1] "" Vector__XXX
 SG_ CellVolt_120 : 51|12@0+ (0.001,0) [0|4.095] "V" Vector__XXX
 SG_ CellNotPresent_120 : 52|1@0+ (1,0) [0|1] "" Vector__XXX

CM_ SG_ 288 Odometer "TIER A confirmed: 32-bit accumulator at 1/64 km. Whole drive 196258->196813 = 555 counts = 8.672 km; dash floor()'d 3066.531 -> 3075.203 as 3066 -> 3075. Mid-drive file shows 29 monotonic +1 steps, proving the low 6 bits are a fraction.";
CM_ BO_ 288 "100 ms, DLC 5. Byte 4 unused (always 0x00). TIER A confirmed";
CM_ SG_ 874 StateOfCharge "TIER A confirmed: four dash matches - 89, 86, 83, 84 % (raw 178/172/166/168).";
CM_ SG_ 874 VehicleSpeed "TIER A confirmed: reads exactly 0 when parked and at the end of the last moving file (dash photo: 0 km/h). Integrated over 4.13 km of driving it lands 2.5% under the odometer - see SPEED SCALE note in docs/MG_WINDSOR_DECODE.md. Uses the same 1/64 quantum as the odometer. Max observed 56.0 km/h.";
CM_ SG_ 874 Checksum "sum(bytes0..6)&0xFF, verified 205/205";
CM_ BO_ 874 "100 ms. Carries SoC AND vehicle speed. TIER A confirmed";
CM_ SG_ 364 VehicleSpeedSigned "TIER A confirmed: sits at exactly 0x8000 when stationary, so it is offset-signed (negative = reverse). Agrees with 0x36A VehicleSpeed to ~1% sample by sample. 10 ms rate makes this the better source for dynamics.";
CM_ BO_ 364 "10 ms. Signed high-resolution speed.";
CM_ SG_ 1221 RangeToEmpty "TIER A confirmed: three dash matches - 284, 274, 263 km. The 12-bit x0.5 alternative yields 1161 and is excluded.";
CM_ BO_ 1221 "100 ms. TIER A confirmed";
CM_ SG_ 666 PackVoltage "Cross-validated: sum of 114 cells == reported pack voltage to 0.011%";
CM_ SG_ 666 HvUnknown_B23 "Static 421.8; possibly a voltage limit. UNCONFIRMED.";
CM_ SG_ 666 PackVoltage2 "Second pack-voltage witness";
CM_ BO_ 666 "50 ms. No checksum on this frame (bytes 6-7 always 0x0000).";
CM_ SG_ 647 PackCurrent "TIER A confirmed: (raw-10000)x0.1. SIGN CONFIRMED - charging log reads -7.0 A (x380.7 V = 2.7 kW slow AC charge, SOC rose 83->84). Positive = discharge. Drive range -23.2 A regen .. +67.1 A.";
CM_ SG_ 647 PackVoltage "Cross-validated: sum of 114 cells == reported pack voltage to 0.011%";
CM_ SG_ 647 AuxCurrent "TIER C. Previously mislabelled a second pack current - it is NOT: it stayed 0..4.9 A while PackCurrent swung -23..+67 A during the drive. Identity unknown (possibly an auxiliary/DC-DC load).";
CM_ SG_ 647 Checksum "sum(bytes0..6)&0xFF, verified 410/410";
CM_ BO_ 647 "50 ms, most dynamic HV frame.";
CM_ SG_ 644 PackVoltage "Cross-validated: sum of 114 cells == reported pack voltage to 0.011%";
CM_ BO_ 644 "100 ms.";
CM_ SG_ 667 CellVoltMax "Matches the 0x5A1-0x5C0 block maximum";
CM_ SG_ 667 CellVoltMaxIndex "Observed 1..113 - fits a 114-cell pack";
CM_ SG_ 667 CellVoltMin "Matches the block minimum exactly";
CM_ SG_ 667 CellVoltAvg "TIER B: reads the block min rather than its mean in some samples.";
CM_ BO_ 667 "100 ms BMS summary. Cross-validated: sum of 114 cells == reported pack voltage to 0.011%";
CM_ SG_ 686 Temp1 "TIER B: 47 C; -40 offset assumed";
CM_ SG_ 686 Temp2 "TIER B: 46 C";
CM_ SG_ 686 Temp3 "TIER B: 46 C";
CM_ SG_ 686 Checksum "sum(bytes0..6)&0xFF, verified 205/205";
CM_ BO_ 686 "100 ms. Sensor identity (module/coolant/ambient) unconfirmed.";
CM_ SG_ 1465 SohPercent "TIER B: reads 88; SOH interpretation unproven";
CM_ SG_ 1465 SocPercent "TIER B: reads 89, agrees with 0x36A at 1 % resolution";
CM_ BO_ 1465 "1 Hz. Inside the cell-block ID range but carries no cell words.";
CM_ SG_ 878 TimeToFullCharge "TIER A: reads 0 in every non-charging capture. Across the five charging captures (one continuous device clock, 118.7-480.8 s) it counts down at -1.01 per minute - so the unit is MINUTES. Read 182 min at 83% SoC on a 2.66 kW AC charge; a naive (17% x 38 kWh)/2.66 kW = 152 min, the BMS being conservative about LFP taper. Modelled 16-bit because byte1 (always 0 here) must carry the high byte for any charge longer than 255 min - UNVERIFIED. A transient 0xFF at buffer start looks like a not-available marker.";
CM_ BO_ 878 "100 ms. Static (all zero) whenever the car is not charging.";
CM_ SG_ 661 ChargingActive "TIER A: discriminates cleanly across all three regimes (parked+AC-on / driving / charging) over 11 captures. 1 = charging.";
CM_ SG_ 661 ChargerCableStatus "TIER A field / TIER B name. Cross-confirmed by the MG Comet EV pack (oem_packs/MG/Comet/EV_2024) — an independent RE of a different MG EV on the same platform, which calls this bit range Charger_Cable_Status at the identical 10|2 position. Reads 0 across 1230 frames of parked/driving and 1 across 769 frames of charging. The 'cable' reading is the Comet author's, not ours: with no plugged-in-but-idle capture we still cannot separate CONNECTED from CHARGING.";
CM_ BO_ 661 "100 ms.";
CM_ SG_ 1158 CellTemp_B6 "TIER B. Cross-confirmed by the MG Comet EV pack (oem_packs/MG/Comet/EV_2024) — an independent RE of a different MG EV on the same platform (Max_cell_Temp at 55|8, offset -40). Windsor readings cool coherently over the session: 53 C parked in the sun -> 49 mid-drive -> 47 after moving and while charging. NOTE the Comet labels byte6 max and byte7 min, but on the Windsor byte6 <= byte7 in every sample, so that max/min assignment does NOT hold here and is deliberately not claimed.";
CM_ SG_ 1158 CellTemp_B7 "TIER B. See CellTemp_B6.";
CM_ BO_ 1158 "100 ms. Frame found only because the Comet pack pointed at it.";
CM_ SG_ 840 VehicleSpeed3 "TIER A: a third speed witness, found via Cross-confirmed by the MG Comet EV pack (oem_packs/MG/Comet/EV_2024) — an independent RE of a different MG EV on the same platform. Scale derived by ratio against our proven 0x36A speed over two files with very different averages (36.5 and 6.9 km/h): implied 0.019938 and 0.019995 — agreeing to 0.3%, so 0.02 km/h (1/50). Reads exactly 0 when parked. The Comet DBC's own 0.0311 does not fit the Windsor.";
CM_ BO_ 840 "10 ms.";
CM_ SG_ 357 PropulsionMode "TIER A: discriminates cleanly across all three regimes (parked+AC-on / driving / charging) over 11 captures. 1 = parked/driving, 0 = charging.";
CM_ SG_ 357 PropulsionMode2 "TIER A: discriminates cleanly across all three regimes (parked+AC-on / driving / charging) over 11 captures. Tracks PropulsionMode.";
CM_ SG_ 357 ChargeMode "TIER A: discriminates cleanly across all three regimes (parked+AC-on / driving / charging) over 11 captures. 1 = charging (inverse of PropulsionMode).";
CM_ BO_ 357 "10 ms. HV system mode - propulsion vs charging.";
CM_ SG_ 1270 ChargerState "TIER B: 0x14 not charging -> 0x08 charging. A charger-type/state enum plausibly lives here, but ONE charger type was captured so no mapping is claimed.";
CM_ SG_ 1270 ChargerParam_B2 "TIER C: 0 unless charging, then 75. Does not reconcile with 2.66 kW at 230 V as either amps or amps/10. Unidentified.";
CM_ SG_ 1270 AcMainsVoltage "TIER B: 0 unless charging, then 230 - exactly Indian mains nominal. Scale 1 V assumed; only one supply voltage was ever seen.";
CM_ BO_ 1270 "100 ms. Only this frame changes shape wholesale when the cable is live, so it is almost certainly the on-board charger.";
CM_ SG_ 341 AccelPedalPos "TIER A confirmed: sweeps the full 0..100 range in the Pedal Position log.";
CM_ SG_ 341 GearSelector "TIER A confirmed: 3=P is constant across EVERY stationary capture; 1=D is constant across every forward-driving file; 2=R occurs in exactly the two files where the 0x16C signed speed goes negative (-4.05 km/h, reversing out of a parking spot) - the two signals confirm each other. 0=N by elimination. Matches the After-Moving dash photo (D).";
CM_ SG_ 341 AccelPedalPos2 "TIER A confirmed: byte-for-byte identical to AccelPedalPos - redundant sensor channel.";
CM_ SG_ 341 PropulsionEnabled "TIER A: discriminates cleanly across all three regimes (parked+AC-on / driving / charging) over 11 captures. 1 = parked/driving, 0 = charging.";
CM_ BO_ 341 "10 ms. Mirrored on MS CAN with identical content.";
CM_ SG_ 298 DoorState_1 "TIER C: a door, position not established (never actuated).";
CM_ SG_ 298 DoorPassenger "TIER A confirmed: 0xAA<->0xBA over two open/close cycles.";
CM_ SG_ 298 DoorState_3 "TIER C: a door, position not established (never actuated).";
CM_ SG_ 298 DoorDriver "TIER A confirmed: 0xAA<->0xAB over three open/close cycles.";
CM_ BO_ 298 "100 ms. Byte 2 = four 2-bit door fields (0xAA = all closed & unlocked). All four read 0 when the car is locked. Driver and passenger verified by event-isolated captures; the other two are unactuated.";
CM_ SG_ 225 DriverSeatBelt "TIER A confirmed: byte1 0x00<->0x08 across two buckle cycles. POLARITY RESOLVED — reads 1 through the whole last moving file, and the dash photo taken at that moment shows 'Fasten the seatbelt'. So 1 = UNBUCKLED.";
CM_ SG_ 225 Checksum "sum(bytes0..6)&0xFF, verified 41/41";
CM_ BO_ 225 "500 ms.";
CM_ SG_ 663 HazardSwitch "TIER B: byte4 0x40 -> 0x00, one clean transition (switch state, not lamp - it does not blink).";
CM_ SG_ 663 TurnUnknown_bit32 "TIER C: byte4 0x80, seen during the Gear log.";
CM_ BO_ 663 "50 ms.";
CM_ SG_ 633 LightSwitchState "TIER B: stepped 2->3->4->5 while the switch was rotated (baseline 2). Position labels NOT established - needs a per-position capture.";
CM_ BO_ 633 "20 ms.";
CM_ SG_ 1083 AcState "TIER B: 1<->2 across the AC toggle. Mirrored on MS CAN.";
CM_ BO_ 1083 "100 ms, present on both HS and MS CAN.";
CM_ SG_ 1008 HvacActive1 "TIER A confirmed: 0 while AC off, ramps 9..22 when on; non-zero in the AC-ON baseline.";
CM_ SG_ 1008 HvacTemp "TIER C: 62..65, possibly a temperature.";
CM_ SG_ 1008 HvacActive2 "TIER A confirmed: tracks HvacActive1.";
CM_ SG_ 1008 HvacActive3 "TIER A confirmed: 0 when off, ramps to 30.";
CM_ BO_ 1008 "MS CAN, 100 ms. The climate frame.";
CM_ SG_ 651 BrakeSignal "TIER B: 0x7C<->0x86 on the brake press (baseline 0x22). Two-state, not a pressure ramp, so the physical meaning is unproven.";
CM_ SG_ 651 BrakeSignal2 "Mirror of BrakeSignal (0x28B duplicates bytes 0-3 into 4-7).";
CM_ BO_ 651 "50 ms.";
CM_ SG_ 1381 ParkBrakeCandidate "TIER C - NOT CONFIRMED. Toggles in the Parking Brake log but ALSO in the Pedal and RPM logs, so it is more likely 'brake applied' or 'stationary' than EPB.";
CM_ BO_ 1381 "100 ms.";
CM_ SG_ 1471 CellVolt_115 "Slot not populated (reads 0xFFF)";
CM_ SG_ 1471 CellVolt_116 "Slot not populated (reads 0xFFF)";
CM_ SG_ 1472 CellVolt_117 "Slot not populated (reads 0xFFF)";
CM_ SG_ 1472 CellVolt_118 "Slot not populated (reads 0xFFF)";
CM_ SG_ 1472 CellVolt_119 "Slot not populated (reads 0xFFF)";
CM_ SG_ 1472 CellVolt_120 "Slot not populated (reads 0xFFF)";
CM_ BO_ 1441 "Cell block 0x5A1-0x5C0 @ 1 Hz. Each 16-bit word = [3-bit slot 1..4][1-bit not-present][12-bit cell mV]; structure verified on 2400/2400 words. On the PRO 98 cells are populated -> 98S (the standard Windsor is 114S). Slots beyond that read 0xFFF. Cell NUMBERING is assumed sequential by ID then word; physical mapping unconfirmed.";
VAL_ 661 ChargerCableStatus 0 "Disconnected" 1 "Connected" ;
VAL_ 341 GearSelector 0 "N" 1 "D" 2 "R" 3 "P" ;
VAL_ 298 DoorState_1 0 "Locked/NotAvailable" 2 "Closed" 3 "Open" ;
VAL_ 298 DoorPassenger 0 "Locked/NotAvailable" 2 "Closed" 3 "Open" ;
VAL_ 298 DoorState_3 0 "Locked/NotAvailable" 2 "Closed" 3 "Open" ;
VAL_ 298 DoorDriver 0 "Locked/NotAvailable" 2 "Closed" 3 "Open" ;
VAL_ 225 DriverSeatBelt 0 "Buckled" 1 "Unbuckled" ;
